# PRU_ICSSG1_PR1_MII_RT_PR1_MII_RT_G_CFG_REGS_G register map
Vendor: Texas Instruments
Peripheral module from a debugger description file (folder am243x).
Registers are 32-bit, read-write, reset 0x0 unless marked. A register's access mark holds for its fields unless they carry their own. Offsets are as the file gives them; lines under a group give offsets from that group; [hi:lo] are bit positions; {n}, {i} and the like mark numbered series; 'fields as' and 'values as' point back to an identical list; <NAME> marks a mode.

## PRU_ICSSG1_PR1_MII_RT_PR1_MII_RT_G_CFG_REGS_G
0x08 PR1_MII_RT__PR1_MII_RT_G_CFG__REGS_G_mac_pru0_0
  [31:0] MAC_PRU0_0 — MAC pru0 DA3:DA0 Used for SAV and DA match
0x0C PR1_MII_RT__PR1_MII_RT_G_CFG__REGS_G_mac_pru0_1
  [15:0] MAC_PRU0_1 — MAC pru0 DA5:DA4 Used for SAV and DA match
0x10 PR1_MII_RT__PR1_MII_RT_G_CFG__REGS_G_mac_pru1_0
  [31:0] MAC_PRU1_0 — MAC pru1 DA3:DA0 Used for SAV and DA match
0x14 PR1_MII_RT__PR1_MII_RT_G_CFG__REGS_G_mac_pru1_1
  [15:0] MAC_PRU1_1 — MAC pru1 DA5:DA4 Used for SAV and DA match
0x18 PR1_MII_RT__PR1_MII_RT_G_CFG__REGS_G_mac_interface_0
  [31:0] MAC_INF_0 — MAC Host interface DA3:DA0 Used for SAV and DA match
0x1C PR1_MII_RT__PR1_MII_RT_G_CFG__REGS_G_mac_interface_1
  [15:0] MAC_INF_1 — MAC Host interface DA5:DA4 Used for SAV and DA match
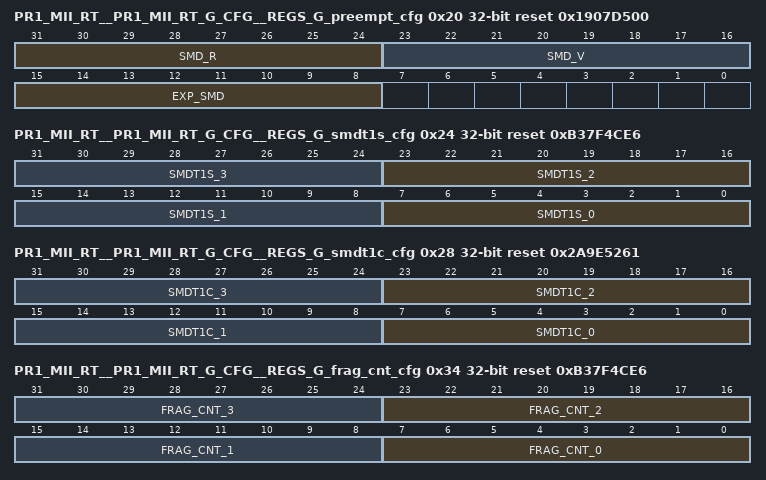
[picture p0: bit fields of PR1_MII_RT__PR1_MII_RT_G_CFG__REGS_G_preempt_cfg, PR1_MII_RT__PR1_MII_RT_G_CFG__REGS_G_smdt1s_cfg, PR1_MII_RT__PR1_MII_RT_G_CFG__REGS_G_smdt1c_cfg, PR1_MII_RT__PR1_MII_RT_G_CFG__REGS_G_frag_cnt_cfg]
0x20 PR1_MII_RT__PR1_MII_RT_G_CFG__REGS_G_preempt_cfg reset 0x1907D500
  [31:24] SMD_R — Response frame TAG
  [23:16] SMD_V — Verification frame TAG
  [15:8] EXP_SMD — None preemptable frame start, or express frame
0x24 PR1_MII_RT__PR1_MII_RT_G_CFG__REGS_G_smdt1s_cfg reset 0xB37F4CE6
  [8n+7:8n] SMDT1S_{n} (n=0..3) — SMDT1S{n} pattern
0x28 PR1_MII_RT__PR1_MII_RT_G_CFG__REGS_G_smdt1c_cfg reset 0x2A9E5261
  [8n+7:8n] SMDT1C_{n} (n=0..3) — SMDT1C{n} pattern
0x34 PR1_MII_RT__PR1_MII_RT_G_CFG__REGS_G_frag_cnt_cfg reset 0xB37F4CE6
  [8n+7:8n] FRAG_CNT_{n} (n=0..3) — FRAG Cnt{n} pattern
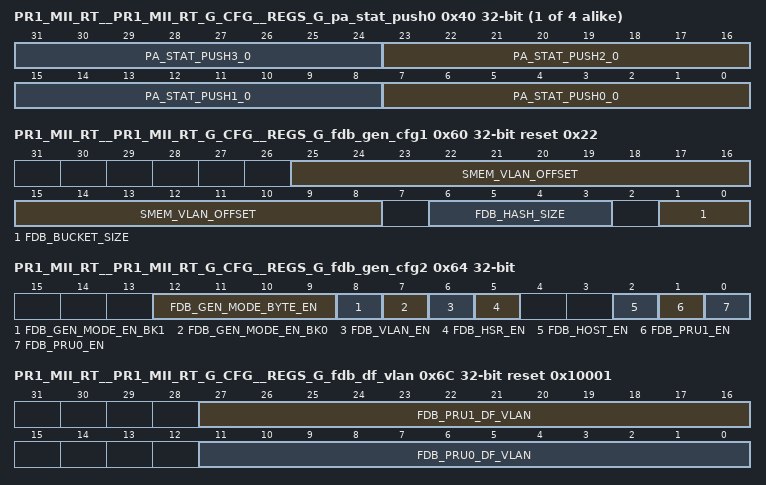
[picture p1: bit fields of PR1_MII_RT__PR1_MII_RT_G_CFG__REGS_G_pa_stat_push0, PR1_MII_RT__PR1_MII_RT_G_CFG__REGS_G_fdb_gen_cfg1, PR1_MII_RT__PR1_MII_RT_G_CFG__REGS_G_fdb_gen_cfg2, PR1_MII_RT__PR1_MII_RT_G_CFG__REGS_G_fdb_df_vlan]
{0x40+4i} PR1_MII_RT__PR1_MII_RT_G_CFG__REGS_G_pa_stat_push{i} (i=0..3)
  [8n+7:8n] PA_STAT_PUSH{n}_{i} (n=0..3) — pa stat push{n}
0x60 PR1_MII_RT__PR1_MII_RT_G_CFG__REGS_G_fdb_gen_cfg1 reset 0x22
  [25:8] SMEM_VLAN_OFFSET — SMEM VLAN FID table base address
  [6:3] FDB_HASH_SIZE — FDB hash size 0:64 1:128 2:256 3:512 4:1024 5:2048
  [1:0] FDB_BUCKET_SIZE — FDB buket size 0:1 1:2 2:4 3:8
0x64 PR1_MII_RT__PR1_MII_RT_G_CFG__REGS_G_fdb_gen_cfg2
  [12:9] FDB_GEN_MODE_BYTE_EN — FDB General Mode Byte compare size 0 = 1 Byte, 15 = 16 Bytes
  [8] FDB_GEN_MODE_EN_BK1 — FDB General Mode Enable Bank1 if set PRU0/PRU1/HOST will get disabled
  [7] FDB_GEN_MODE_EN_BK0 — FDB General Mode Enable Bank0 if set PRU0/PRU1/HOST will get disabled
  [6] FDB_VLAN_EN — FDB Global VLAN Enable
  [5] FDB_HSR_EN — FDB Global HSR Enable note VLAN most be disabled
  [2] FDB_HOST_EN — FDB HOST Enable
  [1] FDB_PRU1_EN — FDB PRU1 Enable
  [0] FDB_PRU0_EN — FDB PRU0 Enable
0x68 PR1_MII_RT__PR1_MII_RT_G_CFG__REGS_G_fdb_gen_status access not given reset not defined
0x6C PR1_MII_RT__PR1_MII_RT_G_CFG__REGS_G_fdb_df_vlan reset 0x10001
  [27:16] FDB_PRU1_DF_VLAN — FDB Default VLAN for PRU1
  [11:0] FDB_PRU0_DF_VLAN — FDB Default VLAN for PRU0
0x70 PR1_MII_RT__PR1_MII_RT_G_CFG__REGS_G_fdb_host_da0
  [31:0] FDB_HOST_DA0 — FDB HOST DA3:0
0x74 PR1_MII_RT__PR1_MII_RT_G_CFG__REGS_G_fdb_host_da1
  [15:0] FDB_HOST_DA1 — FDB HOST DA5:4
0x78 PR1_MII_RT__PR1_MII_RT_G_CFG__REGS_G_fdb_host_sa0
  [31:0] FDB_HOST_SA0 — FDB HOST SA3:0
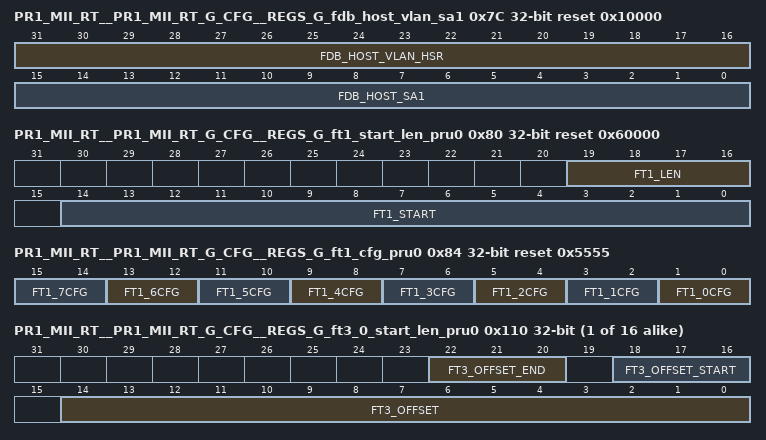
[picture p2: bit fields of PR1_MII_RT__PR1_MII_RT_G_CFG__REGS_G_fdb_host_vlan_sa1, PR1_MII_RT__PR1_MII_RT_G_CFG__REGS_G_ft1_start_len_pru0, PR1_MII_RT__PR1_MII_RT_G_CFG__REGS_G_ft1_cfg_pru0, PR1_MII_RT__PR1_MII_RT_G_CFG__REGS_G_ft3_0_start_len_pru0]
0x7C PR1_MII_RT__PR1_MII_RT_G_CFG__REGS_G_fdb_host_vlan_sa1 reset 0x10000
  [31:16] FDB_HOST_VLAN_HSR — FDB HOST VLAN[11:0] OR HSR[15:0]
  [15:0] FDB_HOST_SA1 — FDB HOST SA5:4
0x80 PR1_MII_RT__PR1_MII_RT_G_CFG__REGS_G_ft1_start_len_pru0 reset 0x60000
  [19:16] FT1_LEN — Defines the total number of Bytes Filter1 will check before Valid bit is set
  [14:0] FT1_START — Byte count start for Filter1. Any wrt will clear all Filter1 Status Bits
0x84 PR1_MII_RT__PR1_MII_RT_G_CFG__REGS_G_ft1_cfg_pru0 reset 0x5555
  [2n+1:2n] FT1_{n}CFG (n=0..7) — 0: Disabled 1: EQ 2: GT 3: LT
{0x88+0x10*i} PR1_MII_RT__PR1_MII_RT_G_CFG__REGS_G_ft1_{i}_da0_pru0 (i=0..7)
  [31:0] FT1_{i}_DA0 — Filter1 DA4:DA1
{0x8C+0x10*i} PR1_MII_RT__PR1_MII_RT_G_CFG__REGS_G_ft1_{i}_da1_pru0 (i=0..7)
  [15:0] FT1_{i}_DA1 — Filter1 DA6:DA5
{0x90+0x10*i} PR1_MII_RT__PR1_MII_RT_G_CFG__REGS_G_ft1_{i}_da_mask0_pru0 (i=0..7)
  [31:0] FT1_{i}_DA_MASK0 — Filter1 MDA4:MDA1 set to 1 to mask that bit
{0x94+0x10*i} PR1_MII_RT__PR1_MII_RT_G_CFG__REGS_G_ft1_{i}_da_mask1_pru0 (i=0..7)
  [15:0] FT1_{i}_DA_MASK1 — Filter1 MDA6:MDA5 set to 1 to mask that bit
{0x108+0x20*i} PR1_MII_RT__PR1_MII_RT_G_CFG__REGS_G_ft3_{i}_start_pru0 reset 0xC (i=0..15)
  [14:0] FT3_START — Byte count start for Filter3. Any wrt will clear all Filter3 Status Bits SW can read to determine next start during Auto
{0x10C+0x20*i} PR1_MII_RT__PR1_MII_RT_G_CFG__REGS_G_ft3_{i}_start_auto_pru0 ro (i=0..15)
  [14:0] FT3_START_AUTO — Byte count start for Auto skip mode
{0x110+0x20*i} PR1_MII_RT__PR1_MII_RT_G_CFG__REGS_G_ft3_{i}_start_len_pru0 (i=0..15)
  [22:20] FT3_OFFSET_END — Defines which byte within FT3_[N]P[63:0] to end the compare at set the Valid flag, rule ft3_offset_end >= ft3_offset_start To disable pattern compare set start and end to zero
  [18:16] FT3_OFFSET_START — Defines which byte within FT3_[N]P[63:0] to start the compare
  [14:0] FT3_OFFSET — Determine which byte to start FT3_[N]P[63:0] operation it will start on the next byte after FT3_T completes if set to zero
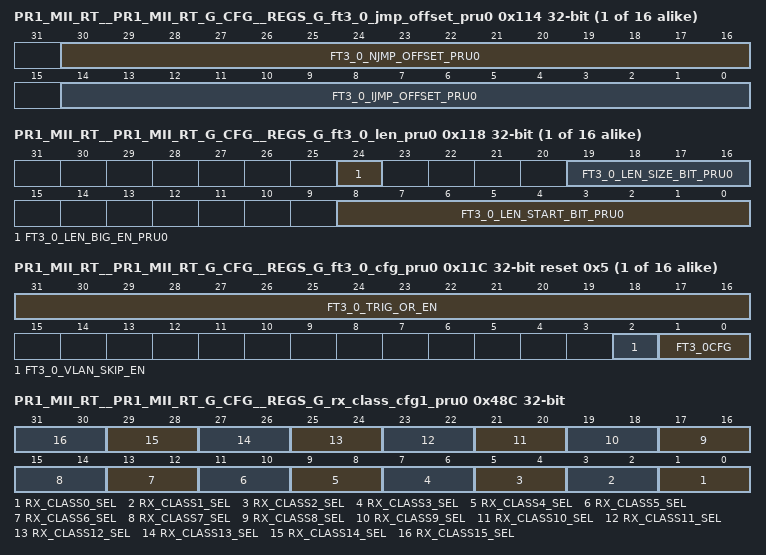
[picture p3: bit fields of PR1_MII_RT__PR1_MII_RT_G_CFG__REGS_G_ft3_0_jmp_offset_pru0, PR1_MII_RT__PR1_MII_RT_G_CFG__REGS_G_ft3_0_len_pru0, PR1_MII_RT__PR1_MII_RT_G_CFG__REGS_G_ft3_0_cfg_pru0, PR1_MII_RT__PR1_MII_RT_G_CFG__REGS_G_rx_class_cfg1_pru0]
{0x114+0x20*i} PR1_MII_RT__PR1_MII_RT_G_CFG__REGS_G_ft3_{i}_jmp_offset_pru0 (i=0..15)
  [30:16] FT3_{i}_NJMP_OFFSET_PRU0 — Defines the Next Offset to compare when auto arm jump is enabled
  [14:0] FT3_{i}_IJMP_OFFSET_PRU0 — Defines the Intial Offset to compare when auto arm jump is enabled
{0x118+0x20*i} PR1_MII_RT__PR1_MII_RT_G_CFG__REGS_G_ft3_{i}_len_pru0 (i=0..15)
  [24] FT3_{i}_LEN_BIG_EN_PRU0 — Enable Big Indian on Length
  [19:16] FT3_{i}_LEN_SIZE_BIT_PRU0 — Defines number of bits to extract the length for the auto skip function
  [8:0] FT3_{i}_LEN_START_BIT_PRU0 — Defines relative bit offset from the HIT byte location upto 512 bit offset the exraction to determine the on the fly length byte offset
{0x11C+0x20*i} PR1_MII_RT__PR1_MII_RT_G_CFG__REGS_G_ft3_{i}_cfg_pru0 reset 0x5 (i=0..15)
  [31:16] FT3_{i}_TRIG_OR_EN — Trigger ft3 select for auto skip enable, if one or more set the function is enabled note you can not slect the same ft3 only others
  [2] FT3_{i}_VLAN_SKIP_EN — 0: Disabled 1: Enable
  [1:0] FT3_{i}CFG — 0: Disabled 1: EQ 2: GT 3: LT
{0x120+0x20*i} PR1_MII_RT__PR1_MII_RT_G_CFG__REGS_G_ft3_{i}_t_pru0 (i=0..15)
  [31:0] FT3_{i}_T — Filter3 T4:T1 Note if Auto Skip is enabled then Type filter is not enabled
{0x124+0x20*i} PR1_MII_RT__PR1_MII_RT_G_CFG__REGS_G_ft3_{i}_t_mask_pru0 (i=0..15)
  [31:0] FT3_{i}_T_MASK — Filter3 MT4:MT1 Note if Auto Skip is enabled then Type filter is not enabled set to 1 to mask that bit
{0x308+0x10*i} PR1_MII_RT__PR1_MII_RT_G_CFG__REGS_G_ft3_{i}_p0_pru0 (i=0..15)
  [31:0] FT3_{i}_P0 — Filter3 P4:P1
{0x30C+0x10*i} PR1_MII_RT__PR1_MII_RT_G_CFG__REGS_G_ft3_{i}_p1_pru0 (i=0..15)
  [31:0] FT3_{i}_P1 — Filter3 P8:P5
{0x310+0x10*i} PR1_MII_RT__PR1_MII_RT_G_CFG__REGS_G_ft3_{i}_p_mask0_pru0 (i=0..15)
  [31:0] FT3_{i}_P_MASK0 — Filter3 MP4:MP1 set to 1 to mask that bit
{0x314+0x10*i} PR1_MII_RT__PR1_MII_RT_G_CFG__REGS_G_ft3_{i}_p_mask1_pru0 (i=0..15)
  [31:0] FT3_{i}_P_MASK1 — Filter3 MP8:MP5 set to 1 to mask that bit
0x408 PR1_MII_RT__PR1_MII_RT_G_CFG__REGS_G_ft_rx_ptr_pru0
  [31:0] FT_RX_PTR_PRU0 — RX current filter Byte Count
{0x40C+8i} PR1_MII_RT__PR1_MII_RT_G_CFG__REGS_G_rx_class{i}_and_en_pru0 (i=0..15)
  [31:0] RX_CLASS{i}_AND_EN — rx class and enabels
{0x410+8i} PR1_MII_RT__PR1_MII_RT_G_CFG__REGS_G_rx_class{i}_or_en_pru0 (i=0..15)
  [31:0] RX_CLASS{i}_OR_EN — rx class or enabels
0x48C PR1_MII_RT__PR1_MII_RT_G_CFG__REGS_G_rx_class_cfg1_pru0
  [2n+1:2n] RX_CLASS{n}_SEL (n=0..15) — rx class final term selection 00: OR 01: AND 10: OR AND AND OR 11: OR OR AND
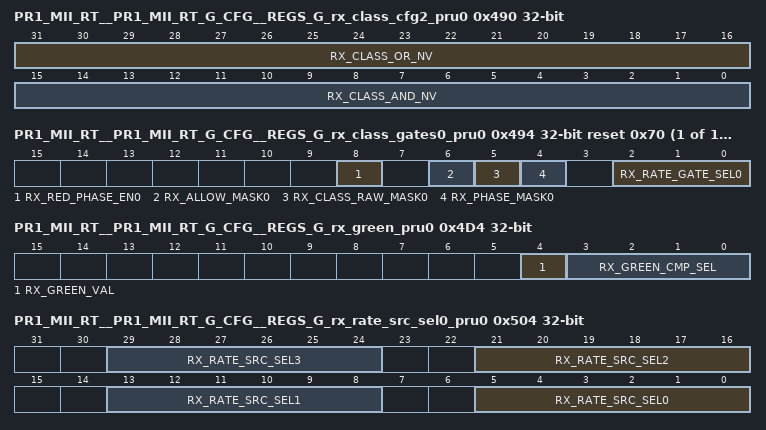
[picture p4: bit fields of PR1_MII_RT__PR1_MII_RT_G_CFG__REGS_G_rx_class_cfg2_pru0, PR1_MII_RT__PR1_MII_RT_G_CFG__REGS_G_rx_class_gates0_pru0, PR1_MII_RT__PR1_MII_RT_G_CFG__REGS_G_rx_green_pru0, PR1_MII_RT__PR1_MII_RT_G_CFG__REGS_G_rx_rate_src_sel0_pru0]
0x490 PR1_MII_RT__PR1_MII_RT_G_CFG__REGS_G_rx_class_cfg2_pru0
  [31:16] RX_CLASS_OR_NV — rx class or nv enable
  [15:0] RX_CLASS_AND_NV — rx class and nv enable
{0x494+4i} PR1_MII_RT__PR1_MII_RT_G_CFG__REGS_G_rx_class_gates{i}_pru0 reset 0x70 (i=0..15)
  [8] RX_RED_PHASE_EN{i} — red phase neable 0: disable 1: enable
  [6] RX_ALLOW_MASK{i} — allow mask 0: unmask 1: mask
  [5] RX_CLASS_RAW_MASK{i} — class raw mask 0: unmask 1: mask
  [4] RX_PHASE_MASK{i} — time phase mask 0: unmask 1: mask
  [2:0] RX_RATE_GATE_SEL{i} — defines which rx_rate will gate rx_class
0x4D4 PR1_MII_RT__PR1_MII_RT_G_CFG__REGS_G_rx_green_pru0 access per field
  [4] RX_GREEN_VAL ro — 0 RED 1 GREEN status
  [3:0] RX_GREEN_CMP_SEL rw — define which IEP CMP start green
0x4D8 PR1_MII_RT__PR1_MII_RT_G_CFG__REGS_G_sa_hash_pru0
  [9:0] SA_HASH_SEED
0x4DC PR1_MII_RT__PR1_MII_RT_G_CFG__REGS_G_conn_hash_pru0
  [9:0] CONN_HASH_SEED — Connection Hash Seed
0x4E0 PR1_MII_RT__PR1_MII_RT_G_CFG__REGS_G_conn_hash_start_pru0
  [14:0] CONN_HASH_START — Connection Hash Start which 4 Bytes to hash
{0x4E4+4i} PR1_MII_RT__PR1_MII_RT_G_CFG__REGS_G_rx_rate_cfg{i}_pru0 (i=0..7)
  [31:0] RX_RATE_CIR_IDLE{i} — RX Rate Peak Information Rate Idle Increment Value - The number added to the PIR counter every clock cycle including EOF. The PIR counter is disabled with a zero value and packets will not be marked RED
0x504 PR1_MII_RT__PR1_MII_RT_G_CFG__REGS_G_rx_rate_src_sel0_pru0
  [8n+5:8n] RX_RATE_SRC_SEL{n} (n=0..3) — Map which filter/flag/class hit that rate logic uses, see table for mapping
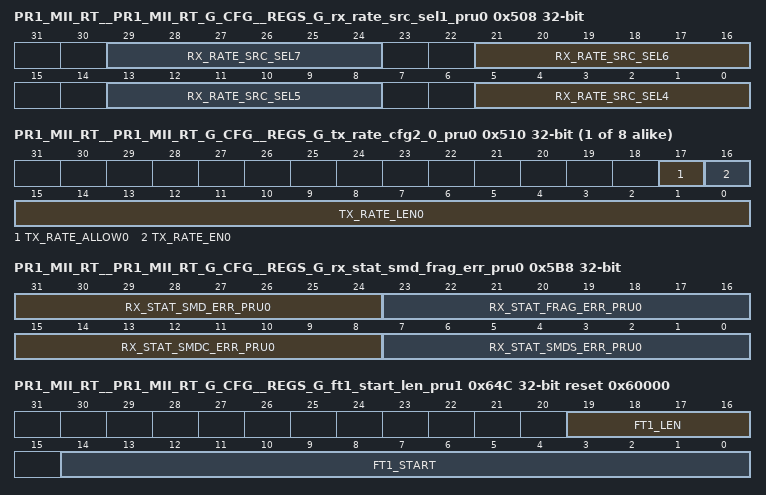
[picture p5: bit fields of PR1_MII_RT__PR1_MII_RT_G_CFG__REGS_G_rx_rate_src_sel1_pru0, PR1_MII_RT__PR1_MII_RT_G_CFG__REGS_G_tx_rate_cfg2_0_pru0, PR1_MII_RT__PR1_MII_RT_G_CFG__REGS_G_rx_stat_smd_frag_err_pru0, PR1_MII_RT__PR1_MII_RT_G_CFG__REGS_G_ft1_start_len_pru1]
0x508 PR1_MII_RT__PR1_MII_RT_G_CFG__REGS_G_rx_rate_src_sel1_pru0
  [8n-27:8n-32] RX_RATE_SRC_SEL{n} (n=4..7) — Map which filter/flag/class hit that rate logic uses, see table for mapping
{0x50C+8i} PR1_MII_RT__PR1_MII_RT_G_CFG__REGS_G_tx_rate_cfg1_{i}_pru0 (i=0..7)
  [31:0] TX_RATE_CIR_IDLE{i} — TX Rate Peak Information Rate Idle Increment Value - The number added to the PIR counter every clock cycle including EOF. The PIR counter is disabled with a zero value and packets will not be marked RED
{0x510+8i} PR1_MII_RT__PR1_MII_RT_G_CFG__REGS_G_tx_rate_cfg2_{i}_pru0 access per field (i=0..7)
  [17] TX_RATE_ALLOW{i} ro — TX Rate Pkt Enable
  [16] TX_RATE_EN{i} rw — TX Rate Pkt Enable
  [15:0] TX_RATE_LEN{i} rw — TX Rate Pkt Length
0x54C PR1_MII_RT__PR1_MII_RT_G_CFG__REGS_G_rx_stat_good_pru0
  [31:0] RX_GOOD_FRM_CNT — RX Good Frame Count Inc on none min err max err crc err odd err, Wrt subtracts
0x550 PR1_MII_RT__PR1_MII_RT_G_CFG__REGS_G_rx_stat_bc_pru0
  [15:0] RX_BC_FRM_CNT — RX BC Frame Count Inc on BC type, Wrt subtracts
0x554 PR1_MII_RT__PR1_MII_RT_G_CFG__REGS_G_rx_stat_mc_pru0
  [15:0] RX_MC_FRM_CNT — RX MC Frame Count Inc on MC type, Wrt subtracts
0x558 PR1_MII_RT__PR1_MII_RT_G_CFG__REGS_G_rx_stat_crc_err_pru0
  [15:0] RX_CRC_ERR_FRM_CNT — RX CRC Err Frame Count Inc on crc err, Wrt subtracts
0x55C PR1_MII_RT__PR1_MII_RT_G_CFG__REGS_G_rx_stat_mii_err_pru0
  [15:0] RX_MII_ERR_FRM_CNT — RX MII Err Frame Count Inc on mii sgmii rgmii err, Wrt subtracts
0x560 PR1_MII_RT__PR1_MII_RT_G_CFG__REGS_G_rx_stat_odd_err_pru0
  [15:0] RX_ODD_ERR_FRM_CNT — RX Odd Nibble Frame Count Inc on odd nibble mii, Wrt subtracts
0x564 PR1_MII_RT__PR1_MII_RT_G_CFG__REGS_G_rx_stat_max_size_pru0 reset 0x7D0
  [15:0] RX_MAX_SIZE_FRM — RX MAX Size Frame Count Limit
0x568 PR1_MII_RT__PR1_MII_RT_G_CFG__REGS_G_rx_stat_max_err_pru0
  [15:0] RX_MAX_ERR_FRM_CNT — RX MAX Size Err Frame Count Inc if > than Limit, Wrt subtracts
0x56C PR1_MII_RT__PR1_MII_RT_G_CFG__REGS_G_rx_stat_min_size_pru0 reset 0x40
  [15:0] RX_MIN_SIZE_FRM — RX MIN Size Frame Limit
0x570 PR1_MII_RT__PR1_MII_RT_G_CFG__REGS_G_rx_stat_min_err_pru0
  [15:0] RX_MIN_ERR_FRM_CNT — RX MIN Size Frame Count Inc if < than limit, Wrt subtracts
0x574 PR1_MII_RT__PR1_MII_RT_G_CFG__REGS_G_rx_stat_overrun_err_pru0
  [15:0] RX_OVERRUN_ERR_FRM_CNT — RX L1 FIFO overflow Frame Count Inc on overflow event, Wrt subtracts
{0x578+4i} PR1_MII_RT__PR1_MII_RT_G_CFG__REGS_G_rx_stat_class{i}_hit_pru0 (i=0..15)
  [31:0] RX_STAT_CLASS{i}_PRU0 — RX Class{i} Hit Count, Wrt subtracts
0x5B8 PR1_MII_RT__PR1_MII_RT_G_CFG__REGS_G_rx_stat_smd_frag_err_pru0
  [31:24] RX_STAT_SMD_ERR_PRU0 — RX SMDS Error Count, Inc when first none 0x55 does not match any valid SMD, Wrt subtracts
  [23:16] RX_STAT_FRAG_ERR_PRU0 — RX Frag_Cnt Seq Error Count, Wrt subtracts
  [15:8] RX_STAT_SMDC_ERR_PRU0 — RX SMDCx Seq Error Count, Wrt subtracts
  [7:0] RX_STAT_SMDS_ERR_PRU0 — RX SMDSx Seq Error Count, Wrt subtracts
0x5BC PR1_MII_RT__PR1_MII_RT_G_CFG__REGS_G_rx_stat_bkt1_size_pru0 reset 0x40
  [13:0] RX_STAT_BKT1_SIZE — RX Bucket1 Byte Size
0x5C0 PR1_MII_RT__PR1_MII_RT_G_CFG__REGS_G_rx_stat_bkt2_size_pru0 reset 0x80
  [13:0] RX_STAT_BKT2_SIZE — RX Bucket2 Byte Size
0x5C4 PR1_MII_RT__PR1_MII_RT_G_CFG__REGS_G_rx_stat_bkt3_size_pru0 reset 0x100
  [13:0] RX_STAT_BKT3_SIZE — RX Bucket3 Byte Size
0x5C8 PR1_MII_RT__PR1_MII_RT_G_CFG__REGS_G_rx_stat_bkt4_size_pru0 reset 0x200
  [13:0] RX_STAT_BKT4_SIZE — RX Bucket4 Byte Size
0x5CC PR1_MII_RT__PR1_MII_RT_G_CFG__REGS_G_rx_stat_64_pru0
  [15:0] RX_64_FRM_CNT — RX 64Byte Frame Count Inc if 64B size
0x5D0 PR1_MII_RT__PR1_MII_RT_G_CFG__REGS_G_rx_stat_bkt1_pru0
  [15:0] RX_STAT_BKT1 — RX Bucket1 Frame Count Inc if <= than Bucket1 Byte Size
{0x5CC+4i} PR1_MII_RT__PR1_MII_RT_G_CFG__REGS_G_rx_stat_bkt{i}_pru0 (i=2..4)
  [15:0] RX_STAT_BKT{i} — RX Bucket{i} Frame Count Inc if <= than Bucket{i} Byte Size and if > than Bucket{i-1} Byte Size
0x5E0 PR1_MII_RT__PR1_MII_RT_G_CFG__REGS_G_rx_stat_bkt5_pru0
  [15:0] RX_STAT_BKT5 — RX Bucket5 Frame Count Inc if > than Bucket4 Byte Size
0x5E4 PR1_MII_RT__PR1_MII_RT_G_CFG__REGS_G_rx_stat_total_bytes_pru0
  [31:0] RX_STAT_TOTAL_BYTES_PRU — RX Total Byte Count
0x5E8 PR1_MII_RT__PR1_MII_RT_G_CFG__REGS_G_rxtx_stat_total_bytes_pru0
  [31:0] RXTX_STAT_TOTAL_BYTES_PRU — RX and TX Total Byte Count
0x5EC PR1_MII_RT__PR1_MII_RT_G_CFG__REGS_G_tx_stat_good_port0
  [31:0] TX_GOOD_FRM_CNT — TX Good Frame Count Inc if no min size err max size err or mii odd nibble
0x5F0 PR1_MII_RT__PR1_MII_RT_G_CFG__REGS_G_tx_stat_bc_port0
  [15:0] TX_BC_FRM_CNT — TX BC Frame Count Inc if BC
0x5F4 PR1_MII_RT__PR1_MII_RT_G_CFG__REGS_G_tx_stat_mc_port0
  [15:0] TX_MC_FRM_CNT — TX MC Frame Count Inc if MC
0x5F8 PR1_MII_RT__PR1_MII_RT_G_CFG__REGS_G_tx_stat_odd_err_port0
  [15:0] TX_ODD_ERR_FRM_CNT — TX Odd Nibble Frame Count Inc if mii odd nibble
0x5FC PR1_MII_RT__PR1_MII_RT_G_CFG__REGS_G_tx_stat_underflow_err_port0
  [15:0] TX_UNDERFLOW_CNT — TX MAX Underflow Error Cnt
0x600 PR1_MII_RT__PR1_MII_RT_G_CFG__REGS_G_tx_stat_max_size_port0 reset 0x7D0
  [15:0] TX_MAX_SIZE_FRM — TX MAX Size Frame Count Limit
0x604 PR1_MII_RT__PR1_MII_RT_G_CFG__REGS_G_tx_stat_max_err_port0
  [15:0] TX_MAX_ERR_FRM_CNT — TX MAX Size Err Frame Count Inc if > max Limit
0x608 PR1_MII_RT__PR1_MII_RT_G_CFG__REGS_G_tx_stat_min_size_port0 reset 0x40
  [15:0] TX_MIN_SIZE_FRM — TX MIN Size Frame Count Limit
0x60C PR1_MII_RT__PR1_MII_RT_G_CFG__REGS_G_tx_stat_min_err_port0
  [15:0] TX_MIN_ERR_FRM_CNT — TX MIN Size Err Frame Count Inc if < min Limit
0x610 PR1_MII_RT__PR1_MII_RT_G_CFG__REGS_G_tx_stat_bkt1_size_port0 reset 0x40
  [13:0] TX_STAT_BKT1_SIZE — TX Bucket1 Byte Size
0x614 PR1_MII_RT__PR1_MII_RT_G_CFG__REGS_G_tx_stat_bkt2_size_port0 reset 0x80
  [13:0] TX_STAT_BKT2_SIZE — TX Bucket2 Byte Size
0x618 PR1_MII_RT__PR1_MII_RT_G_CFG__REGS_G_tx_stat_bkt3_size_port0 reset 0x100
  [13:0] TX_STAT_BKT3_SIZE — TX Bucket3 Byte Size
0x61C PR1_MII_RT__PR1_MII_RT_G_CFG__REGS_G_tx_stat_bkt4_size_port0 reset 0x200
  [13:0] TX_STAT_BKT4_SIZE — TX Bucket4 Byte Size
0x620 PR1_MII_RT__PR1_MII_RT_G_CFG__REGS_G_tx_stat_64_port0
  [15:0] TX_64_FRM_CNT — TX 64Byte Frame Count Inc if 64B
0x624 PR1_MII_RT__PR1_MII_RT_G_CFG__REGS_G_tx_stat_bkt1_port0
  [15:0] TX_STAT_BKT1 — TX Bucket1 Inc if <= than Bucket1
{0x620+4i} PR1_MII_RT__PR1_MII_RT_G_CFG__REGS_G_tx_stat_bkt{i}_port0 (i=2..4)
  [15:0] TX_STAT_BKT{i} — TX Bucket{i} Inc if <= than Bucket{i} Byte Size and if > than Bucket{i-1} Byte Size
0x634 PR1_MII_RT__PR1_MII_RT_G_CFG__REGS_G_tx_stat_bkt5_port0
  [15:0] TX_STAT_BKT5 — TX Bucket5 Inc if > than Bucket4 Byte Size
0x638 PR1_MII_RT__PR1_MII_RT_G_CFG__REGS_G_tx_stat_total_bytes_port0
  [31:0] TX_TOTAL_STAT_BYTES_PORT — TX Total Byte Count of all Frames
0x63C PR1_MII_RT__PR1_MII_RT_G_CFG__REGS_G_tx_hsr_tag_port0 reset 0x892F
  [31:0] TX_HSR_TAG — HSR TAG
0x640 PR1_MII_RT__PR1_MII_RT_G_CFG__REGS_G_tx_hsr_seq_port0
  [15:0] TX_HSR_SEQ — HSR Seq count. It will incr for every HSR type
0x644 PR1_MII_RT__PR1_MII_RT_G_CFG__REGS_G_tx_vlan_type_tag_port0 reset 0x81
  [15:0] TX_VLAN_TYPE_TAG — TX VLAN Type Tag, match to enable VLAN removal
0x648 PR1_MII_RT__PR1_MII_RT_G_CFG__REGS_G_tx_vlan_ins_tag_port0 reset 0x1
  [31:0] TX_VLAN_INS_TAG — TX VLAN Insertion
0x64C PR1_MII_RT__PR1_MII_RT_G_CFG__REGS_G_ft1_start_len_pru1 reset 0x60000
  fields as PR1_MII_RT__PR1_MII_RT_G_CFG__REGS_G_ft1_start_len_pru0
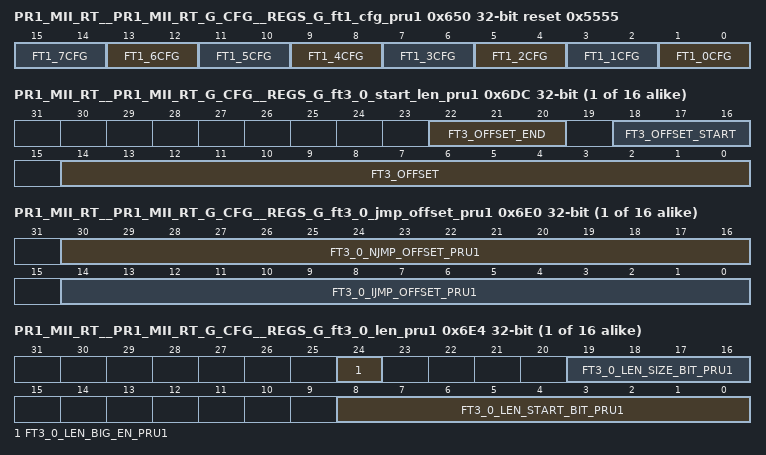
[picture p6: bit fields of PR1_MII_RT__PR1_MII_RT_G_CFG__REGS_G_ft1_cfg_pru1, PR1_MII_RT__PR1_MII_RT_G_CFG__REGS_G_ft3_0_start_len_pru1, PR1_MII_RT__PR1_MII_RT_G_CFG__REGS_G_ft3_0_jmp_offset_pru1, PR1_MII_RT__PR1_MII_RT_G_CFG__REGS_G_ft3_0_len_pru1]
0x650 PR1_MII_RT__PR1_MII_RT_G_CFG__REGS_G_ft1_cfg_pru1 reset 0x5555
  [2n+1:2n] FT1_{n}CFG (n=0..7) — 0: Disabled 1: EQ 2: GT 3: LT
{0x654+0x10*i} PR1_MII_RT__PR1_MII_RT_G_CFG__REGS_G_ft1_{i}_da0_pru1 (i=0..7)
  [31:0] FT1_{i}_DA0 — Filter1 DA4:DA1
{0x658+0x10*i} PR1_MII_RT__PR1_MII_RT_G_CFG__REGS_G_ft1_{i}_da1_pru1 (i=0..7)
  [15:0] FT1_{i}_DA1 — Filter1 DA6:DA5
{0x65C+0x10*i} PR1_MII_RT__PR1_MII_RT_G_CFG__REGS_G_ft1_{i}_da_mask0_pru1 (i=0..7)
  fields as PR1_MII_RT__PR1_MII_RT_G_CFG__REGS_G_ft1_0_da_mask0_pru0
{0x660+0x10*i} PR1_MII_RT__PR1_MII_RT_G_CFG__REGS_G_ft1_{i}_da_mask1_pru1 (i=0..7)
  fields as PR1_MII_RT__PR1_MII_RT_G_CFG__REGS_G_ft1_0_da_mask1_pru0
{0x6D4+0x20*i} PR1_MII_RT__PR1_MII_RT_G_CFG__REGS_G_ft3_{i}_start_pru1 reset 0xC (i=0..15)
  fields as PR1_MII_RT__PR1_MII_RT_G_CFG__REGS_G_ft3_0_start_pru0
{0x6D8+0x20*i} PR1_MII_RT__PR1_MII_RT_G_CFG__REGS_G_ft3_{i}_start_auto_pru1 ro (i=0..15)
  [14:0] FT3_START_AUTO — Byte count start for Auto skip mode
{0x6DC+0x20*i} PR1_MII_RT__PR1_MII_RT_G_CFG__REGS_G_ft3_{i}_start_len_pru1 (i=0..15)
  fields as PR1_MII_RT__PR1_MII_RT_G_CFG__REGS_G_ft3_0_start_len_pru0
{0x6E0+0x20*i} PR1_MII_RT__PR1_MII_RT_G_CFG__REGS_G_ft3_{i}_jmp_offset_pru1 (i=0..15)
  [30:16] FT3_{i}_NJMP_OFFSET_PRU1 — Defines the Next Offset to compare when auto arm jump is enabled
  [14:0] FT3_{i}_IJMP_OFFSET_PRU1 — Defines the Intial Offset to compare when auto arm jump is enabled
{0x6E4+0x20*i} PR1_MII_RT__PR1_MII_RT_G_CFG__REGS_G_ft3_{i}_len_pru1 (i=0..15)
  [24] FT3_{i}_LEN_BIG_EN_PRU1 — Enable Big Indian on Length
  [19:16] FT3_{i}_LEN_SIZE_BIT_PRU1 — Defines number of bits to extract the length for the auto skip function
  [8:0] FT3_{i}_LEN_START_BIT_PRU1 — Defines relative bit offset from the HIT byte location upto 512 bit offset the exraction to determine the on the fly length byte offset
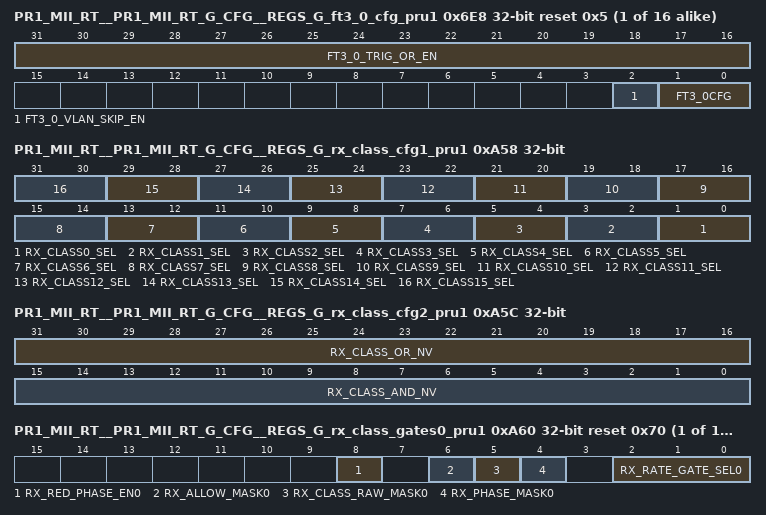
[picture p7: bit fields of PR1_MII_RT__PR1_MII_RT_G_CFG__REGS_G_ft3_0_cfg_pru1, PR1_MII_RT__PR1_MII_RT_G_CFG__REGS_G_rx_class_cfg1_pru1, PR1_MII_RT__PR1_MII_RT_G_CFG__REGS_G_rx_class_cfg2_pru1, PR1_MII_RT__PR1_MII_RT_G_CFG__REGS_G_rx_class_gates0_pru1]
{0x6E8+0x20*i} PR1_MII_RT__PR1_MII_RT_G_CFG__REGS_G_ft3_{i}_cfg_pru1 reset 0x5 (i=0..15)
  fields as PR1_MII_RT__PR1_MII_RT_G_CFG__REGS_G_ft3_0_cfg_pru0
{0x6EC+0x20*i} PR1_MII_RT__PR1_MII_RT_G_CFG__REGS_G_ft3_{i}_t_pru1 (i=0..15)
  fields as PR1_MII_RT__PR1_MII_RT_G_CFG__REGS_G_ft3_0_t_pru0
{0x6F0+0x20*i} PR1_MII_RT__PR1_MII_RT_G_CFG__REGS_G_ft3_{i}_t_mask_pru1 (i=0..15)
  fields as PR1_MII_RT__PR1_MII_RT_G_CFG__REGS_G_ft3_0_t_mask_pru0
{0x8D4+0x10*i} PR1_MII_RT__PR1_MII_RT_G_CFG__REGS_G_ft3_{i}_p0_pru1 (i=0..15)
  [31:0] FT3_{i}_P0 — Filter3 P4:P1
{0x8D8+0x10*i} PR1_MII_RT__PR1_MII_RT_G_CFG__REGS_G_ft3_{i}_p1_pru1 (i=0..15)
  [31:0] FT3_{i}_P1 — Filter3 P8:P5
{0x8DC+0x10*i} PR1_MII_RT__PR1_MII_RT_G_CFG__REGS_G_ft3_{i}_p_mask0_pru1 (i=0..15)
  [31:0] FT3_{i}_P_MASK0 — Filter3 MP4:MP1 set to 1 to mask that bit
{0x8E0+0x10*i} PR1_MII_RT__PR1_MII_RT_G_CFG__REGS_G_ft3_{i}_p_mask1_pru1 (i=0..15)
  [31:0] FT3_{i}_P_MASK1 — Filter3 MP8:MP5 set to 1 to mask that bit
0x9D4 PR1_MII_RT__PR1_MII_RT_G_CFG__REGS_G_ft_rx_ptr_pru1
  [31:0] FT_RX_PTR_PRU1 — RX current filter Byte Count
{0x9D8+8i} PR1_MII_RT__PR1_MII_RT_G_CFG__REGS_G_rx_class{i}_and_en_pru1 (i=0..15)
  [31:0] RX_CLASS{i}_AND_EN — rx class and enabels
{0x9DC+8i} PR1_MII_RT__PR1_MII_RT_G_CFG__REGS_G_rx_class{i}_or_en_pru1 (i=0..15)
  [31:0] RX_CLASS{i}_OR_EN — rx class or enabels
0xA58 PR1_MII_RT__PR1_MII_RT_G_CFG__REGS_G_rx_class_cfg1_pru1
  fields as PR1_MII_RT__PR1_MII_RT_G_CFG__REGS_G_rx_class_cfg1_pru0
0xA5C PR1_MII_RT__PR1_MII_RT_G_CFG__REGS_G_rx_class_cfg2_pru1
  fields as PR1_MII_RT__PR1_MII_RT_G_CFG__REGS_G_rx_class_cfg2_pru0
{0xA60+4i} PR1_MII_RT__PR1_MII_RT_G_CFG__REGS_G_rx_class_gates{i}_pru1 reset 0x70 (i=0..15)
  fields as PR1_MII_RT__PR1_MII_RT_G_CFG__REGS_G_rx_class_gates0_pru0
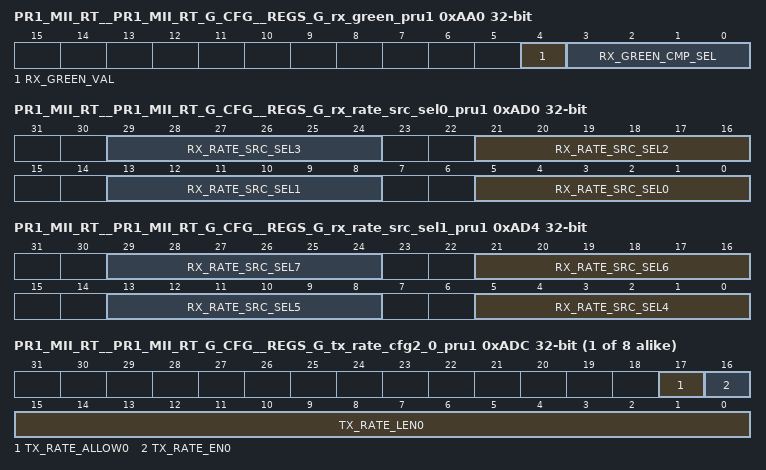
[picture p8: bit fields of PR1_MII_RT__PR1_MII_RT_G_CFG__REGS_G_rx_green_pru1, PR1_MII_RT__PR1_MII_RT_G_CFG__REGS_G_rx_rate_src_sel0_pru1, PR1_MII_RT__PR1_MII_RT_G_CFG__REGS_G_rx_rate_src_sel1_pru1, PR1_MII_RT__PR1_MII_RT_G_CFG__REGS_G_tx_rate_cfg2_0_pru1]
0xAA0 PR1_MII_RT__PR1_MII_RT_G_CFG__REGS_G_rx_green_pru1 access per field
  fields as PR1_MII_RT__PR1_MII_RT_G_CFG__REGS_G_rx_green_pru0
0xAA4 PR1_MII_RT__PR1_MII_RT_G_CFG__REGS_G_sa_hash_pru1
  [9:0] SA_HASH_SEED
0xAA8 PR1_MII_RT__PR1_MII_RT_G_CFG__REGS_G_conn_hash_pru1
  [9:0] CONN_HASH_SEED — Connection Hash Seed
0xAAC PR1_MII_RT__PR1_MII_RT_G_CFG__REGS_G_conn_hash_start_pru1
  [14:0] CONN_HASH_START — Connection Hash Start which 4 Bytes to hash
{0xAB0+4i} PR1_MII_RT__PR1_MII_RT_G_CFG__REGS_G_rx_rate_cfg{i}_pru1 (i=0..7)
  fields as PR1_MII_RT__PR1_MII_RT_G_CFG__REGS_G_rx_rate_cfg0_pru0
0xAD0 PR1_MII_RT__PR1_MII_RT_G_CFG__REGS_G_rx_rate_src_sel0_pru1
  fields as PR1_MII_RT__PR1_MII_RT_G_CFG__REGS_G_rx_rate_src_sel0_pru0
0xAD4 PR1_MII_RT__PR1_MII_RT_G_CFG__REGS_G_rx_rate_src_sel1_pru1
  fields as PR1_MII_RT__PR1_MII_RT_G_CFG__REGS_G_rx_rate_src_sel1_pru0
{0xAD8+8i} PR1_MII_RT__PR1_MII_RT_G_CFG__REGS_G_tx_rate_cfg1_{i}_pru1 (i=0..7)
  fields as PR1_MII_RT__PR1_MII_RT_G_CFG__REGS_G_tx_rate_cfg1_0_pru0
{0xADC+8i} PR1_MII_RT__PR1_MII_RT_G_CFG__REGS_G_tx_rate_cfg2_{i}_pru1 access per field (i=0..7)
  fields as PR1_MII_RT__PR1_MII_RT_G_CFG__REGS_G_tx_rate_cfg2_0_pru0
0xB18 PR1_MII_RT__PR1_MII_RT_G_CFG__REGS_G_rx_stat_good_pru1
  fields as PR1_MII_RT__PR1_MII_RT_G_CFG__REGS_G_rx_stat_good_pru0
0xB1C PR1_MII_RT__PR1_MII_RT_G_CFG__REGS_G_rx_stat_bc_pru1
  fields as PR1_MII_RT__PR1_MII_RT_G_CFG__REGS_G_rx_stat_bc_pru0
0xB20 PR1_MII_RT__PR1_MII_RT_G_CFG__REGS_G_rx_stat_mc_pru1
  fields as PR1_MII_RT__PR1_MII_RT_G_CFG__REGS_G_rx_stat_mc_pru0
0xB24 PR1_MII_RT__PR1_MII_RT_G_CFG__REGS_G_rx_stat_crc_err_pru1
  fields as PR1_MII_RT__PR1_MII_RT_G_CFG__REGS_G_rx_stat_crc_err_pru0
0xB28 PR1_MII_RT__PR1_MII_RT_G_CFG__REGS_G_rx_stat_mii_err_pru1
  fields as PR1_MII_RT__PR1_MII_RT_G_CFG__REGS_G_rx_stat_mii_err_pru0
0xB2C PR1_MII_RT__PR1_MII_RT_G_CFG__REGS_G_rx_stat_odd_err_pru1
  fields as PR1_MII_RT__PR1_MII_RT_G_CFG__REGS_G_rx_stat_odd_err_pru0
0xB30 PR1_MII_RT__PR1_MII_RT_G_CFG__REGS_G_rx_stat_max_size_pru1 reset 0x7D0
  [15:0] RX_MAX_SIZE_FRM — RX MAX Size Frame Count Limit
0xB34 PR1_MII_RT__PR1_MII_RT_G_CFG__REGS_G_rx_stat_max_err_pru1
  fields as PR1_MII_RT__PR1_MII_RT_G_CFG__REGS_G_rx_stat_max_err_pru0
0xB38 PR1_MII_RT__PR1_MII_RT_G_CFG__REGS_G_rx_stat_min_size_pru1 reset 0x40
  [15:0] RX_MIN_SIZE_FRM — RX MIN Size Frame Limit
0xB3C PR1_MII_RT__PR1_MII_RT_G_CFG__REGS_G_rx_stat_min_err_pru1
  fields as PR1_MII_RT__PR1_MII_RT_G_CFG__REGS_G_rx_stat_min_err_pru0
0xB40 PR1_MII_RT__PR1_MII_RT_G_CFG__REGS_G_rx_stat_overrun_err_pru1
  fields as PR1_MII_RT__PR1_MII_RT_G_CFG__REGS_G_rx_stat_overrun_err_pru0
{0xB44+4i} PR1_MII_RT__PR1_MII_RT_G_CFG__REGS_G_rx_stat_class{i}_hit_pru1 (i=0..15)
  [31:0] RX_STAT_CLASS{i}_PRU1 — RX Class{i} Hit Count, Wrt subtracts
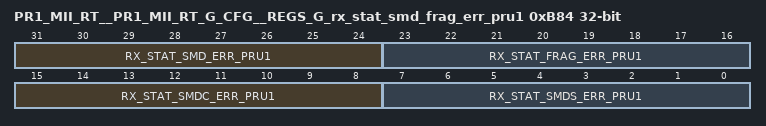
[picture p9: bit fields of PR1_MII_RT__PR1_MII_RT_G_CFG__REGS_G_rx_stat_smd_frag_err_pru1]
0xB84 PR1_MII_RT__PR1_MII_RT_G_CFG__REGS_G_rx_stat_smd_frag_err_pru1
  [31:24] RX_STAT_SMD_ERR_PRU1 — RX SMDS Error Count, Inc when first none 0x55 does not match any valid SMD, Wrt subtracts
  [23:16] RX_STAT_FRAG_ERR_PRU1 — RX Frag_Cnt Seq Error Count, Wrt subtracts
  [15:8] RX_STAT_SMDC_ERR_PRU1 — RX SMDCx Seq Error Count, Wrt subtracts
  [7:0] RX_STAT_SMDS_ERR_PRU1 — RX SMDSx Seq Error Count, Wrt subtracts
0xB88 PR1_MII_RT__PR1_MII_RT_G_CFG__REGS_G_rx_stat_bkt1_size_pru1 reset 0x40
  [13:0] RX_STAT_BKT1_SIZE — RX Bucket1 Byte Size
0xB8C PR1_MII_RT__PR1_MII_RT_G_CFG__REGS_G_rx_stat_bkt2_size_pru1 reset 0x80
  [13:0] RX_STAT_BKT2_SIZE — RX Bucket2 Byte Size
0xB90 PR1_MII_RT__PR1_MII_RT_G_CFG__REGS_G_rx_stat_bkt3_size_pru1 reset 0x100
  [13:0] RX_STAT_BKT3_SIZE — RX Bucket3 Byte Size
0xB94 PR1_MII_RT__PR1_MII_RT_G_CFG__REGS_G_rx_stat_bkt4_size_pru1 reset 0x200
  [13:0] RX_STAT_BKT4_SIZE — RX Bucket4 Byte Size
0xB98 PR1_MII_RT__PR1_MII_RT_G_CFG__REGS_G_rx_stat_64_pru1
  [15:0] RX_64_FRM_CNT — RX 64Byte Frame Count Inc if 64B size
0xB9C PR1_MII_RT__PR1_MII_RT_G_CFG__REGS_G_rx_stat_bkt1_pru1
  fields as PR1_MII_RT__PR1_MII_RT_G_CFG__REGS_G_rx_stat_bkt1_pru0
{0xB98+4i} PR1_MII_RT__PR1_MII_RT_G_CFG__REGS_G_rx_stat_bkt{i}_pru1 (i=2..4)
  fields as PR1_MII_RT__PR1_MII_RT_G_CFG__REGS_G_rx_stat_bkt2_pru0
0xBAC PR1_MII_RT__PR1_MII_RT_G_CFG__REGS_G_rx_stat_bkt5_pru1
  fields as PR1_MII_RT__PR1_MII_RT_G_CFG__REGS_G_rx_stat_bkt5_pru0
0xBB0 PR1_MII_RT__PR1_MII_RT_G_CFG__REGS_G_rx_stat_total_bytes_pru1
  [31:0] RX_STAT_TOTAL_BYTES_PRU — RX Total Byte Count
0xBB4 PR1_MII_RT__PR1_MII_RT_G_CFG__REGS_G_rxtx_stat_total_bytes_pru1
  [31:0] RXTX_STAT_TOTAL_BYTES_PRU — RX and TX Total Byte Count
0xBB8 PR1_MII_RT__PR1_MII_RT_G_CFG__REGS_G_tx_stat_good_port1
  fields as PR1_MII_RT__PR1_MII_RT_G_CFG__REGS_G_tx_stat_good_port0
0xBBC PR1_MII_RT__PR1_MII_RT_G_CFG__REGS_G_tx_stat_bc_port1
  [15:0] TX_BC_FRM_CNT — TX BC Frame Count Inc if BC
0xBC0 PR1_MII_RT__PR1_MII_RT_G_CFG__REGS_G_tx_stat_mc_port1
  [15:0] TX_MC_FRM_CNT — TX MC Frame Count Inc if MC
0xBC4 PR1_MII_RT__PR1_MII_RT_G_CFG__REGS_G_tx_stat_odd_err_port1
  fields as PR1_MII_RT__PR1_MII_RT_G_CFG__REGS_G_tx_stat_odd_err_port0
0xBC8 PR1_MII_RT__PR1_MII_RT_G_CFG__REGS_G_tx_stat_underflow_err_port1
  [15:0] TX_UNDERFLOW_CNT — TX MAX Underflow Error Cnt
0xBCC PR1_MII_RT__PR1_MII_RT_G_CFG__REGS_G_tx_stat_max_size_port1 reset 0x7D0
  [15:0] TX_MAX_SIZE_FRM — TX MAX Size Frame Count Limit
0xBD0 PR1_MII_RT__PR1_MII_RT_G_CFG__REGS_G_tx_stat_max_err_port1
  fields as PR1_MII_RT__PR1_MII_RT_G_CFG__REGS_G_tx_stat_max_err_port0
0xBD4 PR1_MII_RT__PR1_MII_RT_G_CFG__REGS_G_tx_stat_min_size_port1 reset 0x40
  [15:0] TX_MIN_SIZE_FRM — TX MIN Size Frame Count Limit
0xBD8 PR1_MII_RT__PR1_MII_RT_G_CFG__REGS_G_tx_stat_min_err_port1
  fields as PR1_MII_RT__PR1_MII_RT_G_CFG__REGS_G_tx_stat_min_err_port0
0xBDC PR1_MII_RT__PR1_MII_RT_G_CFG__REGS_G_tx_stat_bkt1_size_port1 reset 0x40
  [13:0] TX_STAT_BKT1_SIZE — TX Bucket1 Byte Size
0xBE0 PR1_MII_RT__PR1_MII_RT_G_CFG__REGS_G_tx_stat_bkt2_size_port1 reset 0x80
  [13:0] TX_STAT_BKT2_SIZE — TX Bucket2 Byte Size
0xBE4 PR1_MII_RT__PR1_MII_RT_G_CFG__REGS_G_tx_stat_bkt3_size_port1 reset 0x100
  [13:0] TX_STAT_BKT3_SIZE — TX Bucket3 Byte Size
0xBE8 PR1_MII_RT__PR1_MII_RT_G_CFG__REGS_G_tx_stat_bkt4_size_port1 reset 0x200
  [13:0] TX_STAT_BKT4_SIZE — TX Bucket4 Byte Size
0xBEC PR1_MII_RT__PR1_MII_RT_G_CFG__REGS_G_tx_stat_64_port1
  [15:0] TX_64_FRM_CNT — TX 64Byte Frame Count Inc if 64B
0xBF0 PR1_MII_RT__PR1_MII_RT_G_CFG__REGS_G_tx_stat_bkt1_port1
  [15:0] TX_STAT_BKT1 — TX Bucket1 Inc if <= than Bucket1
{0xBEC+4i} PR1_MII_RT__PR1_MII_RT_G_CFG__REGS_G_tx_stat_bkt{i}_port1 (i=2..4)
  fields as PR1_MII_RT__PR1_MII_RT_G_CFG__REGS_G_tx_stat_bkt2_port0
0xC00 PR1_MII_RT__PR1_MII_RT_G_CFG__REGS_G_tx_stat_bkt5_port1
  [15:0] TX_STAT_BKT5 — TX Bucket5 Inc if > than Bucket4 Byte Size
0xC04 PR1_MII_RT__PR1_MII_RT_G_CFG__REGS_G_tx_stat_total_bytes_port1
  [31:0] TX_TOTAL_STAT_BYTES_PORT — TX Total Byte Count of all Frames
0xC08 PR1_MII_RT__PR1_MII_RT_G_CFG__REGS_G_tx_hsr_tag_port1 reset 0x892F
  [31:0] TX_HSR_TAG — HSR TAG
0xC0C PR1_MII_RT__PR1_MII_RT_G_CFG__REGS_G_tx_hsr_seq_port1
  [15:0] TX_HSR_SEQ — HSR Seq count. It will incr for every HSR type
0xC10 PR1_MII_RT__PR1_MII_RT_G_CFG__REGS_G_tx_vlan_type_tag_port1 reset 0x81
  fields as PR1_MII_RT__PR1_MII_RT_G_CFG__REGS_G_tx_vlan_type_tag_port0
0xC14 PR1_MII_RT__PR1_MII_RT_G_CFG__REGS_G_tx_vlan_ins_tag_port1 reset 0x1
  [31:0] TX_VLAN_INS_TAG — TX VLAN Insertion
{0xD00+4i} PR1_MII_RT__PR1_MII_RT_G_CFG__REGS_G_queue{i} (i=0..63)
  [15:0] QUEUE_H_PTR{i} — Queue {i}
{0xE00+4i} PR1_MII_RT__PR1_MII_RT_G_CFG__REGS_G_queue_peek{i} ro (i=0..15)
  [15:0] QUEUE_H_PEEK_PTR{i} — Queue {i} Peek portal
{0xE40+4i} PR1_MII_RT__PR1_MII_RT_G_CFG__REGS_G_queue_cnt{i} ro (i=0..63)
  [15:0] QUEUE_CNT_ENTRIES_{i} — Queue Entry Count{i}
0xF40 PR1_MII_RT__PR1_MII_RT_G_CFG__REGS_G_queue_reset
  [5:0] RESET_QUEUE_ID
